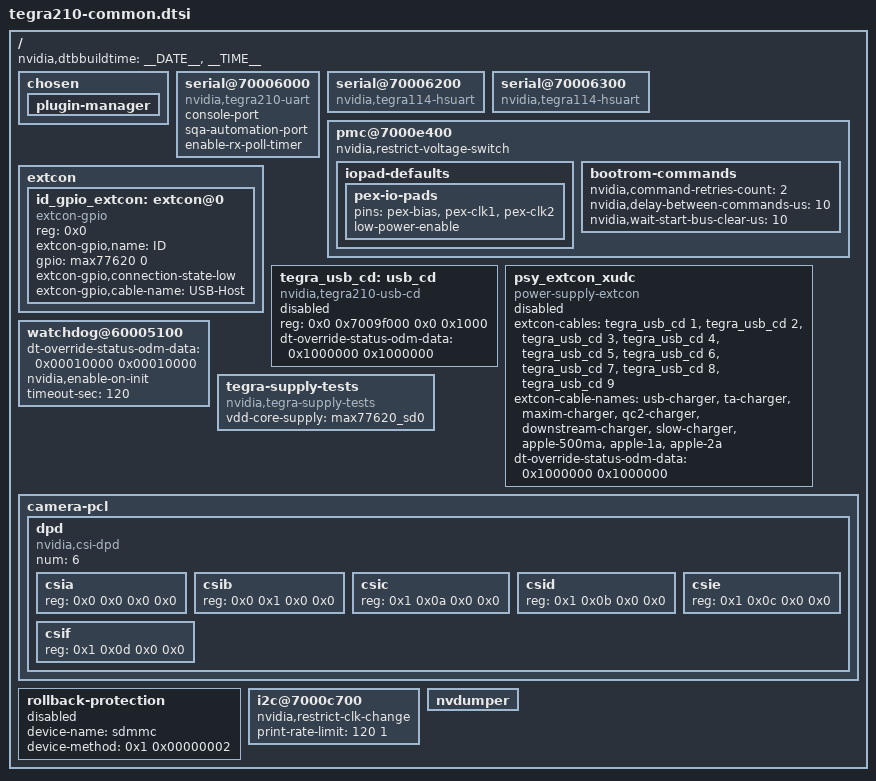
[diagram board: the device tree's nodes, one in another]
/*
 * Copyright (c) 2014-2017, NVIDIA CORPORATION.  All rights reserved.
 *
 * This program is free software; you can redistribute it and/or modify
 * it under the terms of the GNU General Public License as published by
 * the Free Software Foundation; either version 2 of the License, or
 * (at your option) any later version.
 *
 * This program is distributed in the hope that it will be useful, but WITHOUT
 * ANY WARRANTY; without even the implied warranty of MERCHANTABILITY or
 * FITNESS FOR A PARTICULAR PURPOSE.  See the GNU General Public License for
 * more details.
 *
 * You should have received a copy of the GNU General Public License along
 * with this program; if not, write to the Free Software Foundation, Inc.,
 * 51 Franklin Street, Fifth Floor, Boston, MA  02110-1301, USA.
 */

#include <tegra210-soc/tegra210-soc-shield.dtsi>
#include <dt-bindings/interrupt-controller/arm-gic.h>
#include <dt-bindings/gpio/tegra-gpio.h>
#include <tegra210-soc/tegra210-prods.dtsi>
#include <t210-common-platforms/tegra210-platform-common-padvoltage-default.dtsi>
#include <t210-common-platforms/tegra210-ers-touch-e1937-1000-a00.dtsi>
#include <tegra210-soc/tegra210-modem-common.dtsi>
#include <tegra210-soc/tegra210-trusty.dtsi>

/ {
	nvidia,dtbbuildtime = __DATE__, __TIME__;

	chosen {
		plugin-manager {
		};
	};

	serial@70006000 {
		compatible = "nvidia,tegra210-uart", "nvidia,tegra114-hsuart";
		console-port;
		sqa-automation-port;
		enable-rx-poll-timer;
		/delete-property/ resets;
		/delete-property/ reset-names;
		status = "okay";
	};

	serial@70006200 {
		compatible = "nvidia,tegra114-hsuart";
		status = "okay";
	};

	serial@70006300 {
		compatible = "nvidia,tegra114-hsuart";
		status = "okay";
	};

	pmc@7000e400 {
		nvidia,restrict-voltage-switch;
                iopad-defaults {
                        pex-io-pads {
				pins = "pex-bias", "pex-clk1", "pex-clk2";
				low-power-enable;
			};
		};

		bootrom-commands {
			nvidia,command-retries-count = <2>;
			nvidia,delay-between-commands-us = <10>;
			nvidia,wait-start-bus-clear-us = <10>;
			#address-cells = <1>;
			#size-cells = <0>;
		};
	};

	extcon {
		id_gpio_extcon: extcon@0 {
			compatible = "extcon-gpio";
			reg = <0x0>;
			extcon-gpio,name = "ID";
			gpio = <&max77620 0 0>;
			extcon-gpio,connection-state-low;
			extcon-gpio,cable-name = "USB-Host";
			#extcon-cells = <1>;
		};
	};

	tegra_usb_cd: usb_cd {
		compatible = "nvidia,tegra210-usb-cd";
		reg = <0x0 0x7009f000 0x0 0x1000>;
		#extcon-cells = <1>;
		status = "disabled";
		dt-override-status-odm-data = <0x1000000 0x1000000>;
	};

	psy_extcon_xudc {
		compatible = "power-supply-extcon";
		extcon-cables = <&tegra_usb_cd 1 &tegra_usb_cd 2 &tegra_usb_cd 3
				&tegra_usb_cd 4 &tegra_usb_cd 5 &tegra_usb_cd 6
				&tegra_usb_cd 7 &tegra_usb_cd 8 &tegra_usb_cd 9>;
		extcon-cable-names = "usb-charger", "ta-charger", "maxim-charger",
				"qc2-charger", "downstream-charger", "slow-charger",
				"apple-500ma", "apple-1a", "apple-2a";
		status = "disabled";
		dt-override-status-odm-data = <0x1000000 0x1000000>;
	};

	watchdog@60005100 {
		dt-override-status-odm-data = <0x00010000 0x00010000>;
		nvidia,enable-on-init;
		timeout-sec = <120>;
	};

	tegra-supply-tests {
		compatible = "nvidia,tegra-supply-tests";
		vdd-core-supply=<&max77620_sd0>;
	};

	camera-pcl {
		dpd {
			compatible = "nvidia,csi-dpd";
			#address-cells = <1>;
			#size-cells = <0>;
			num = <6>;
			csia {
				reg = <0x0 0x0 0x0 0x0>;
			};
			csib {
				reg = <0x0 0x1 0x0 0x0>;
			};
			csic {
				reg = <0x1 0x0a 0x0 0x0>;
			};
			csid {
				reg = <0x1 0x0b 0x0 0x0>;
			};
			csie {
				reg = <0x1 0x0c 0x0 0x0>;
			};
			csif {
				reg = <0x1 0x0d 0x0 0x0>;
			};
		};
	};

	rollback-protection {
		device-name = "sdmmc";
		device-method = <0x1 0x00000002>;  /* type (0x1 = ioctl), argument */
		status = "disabled";
	};

	i2c@7000c700 {
		nvidia,restrict-clk-change;
		print-rate-limit = <120 1>;
	};

	nvdumper {
		status = "okay";
	};
};
